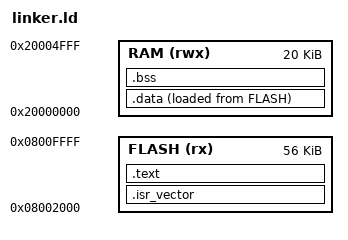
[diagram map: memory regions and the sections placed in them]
/* Application linker — offset so bootloader owns 0x08000000..0x08001FFF.
   Flash separately:  st-flash write app.bin 0x08002000 */

ENTRY(Reset_Handler)

MEMORY
{
    FLASH (rx)  : ORIGIN = 0x08002000, LENGTH = 56K
    RAM   (rwx) : ORIGIN = 0x20000000, LENGTH = 20K
}

_estack = ORIGIN(RAM) + LENGTH(RAM);

SECTIONS
{
    .isr_vector :
    {
        KEEP(*(.isr_vector))
    } > FLASH

    .text :
    {
        *(.text*)
        *(.rodata*)
    } > FLASH

    .data :
    {
        _sdata = .;
        *(.data*)
        _edata = .;
    } > RAM AT > FLASH
    _sidata = LOADADDR(.data);

    .bss :
    {
        _sbss = .;
        *(.bss*)
        *(COMMON)
        _ebss = .;
    } > RAM
}
